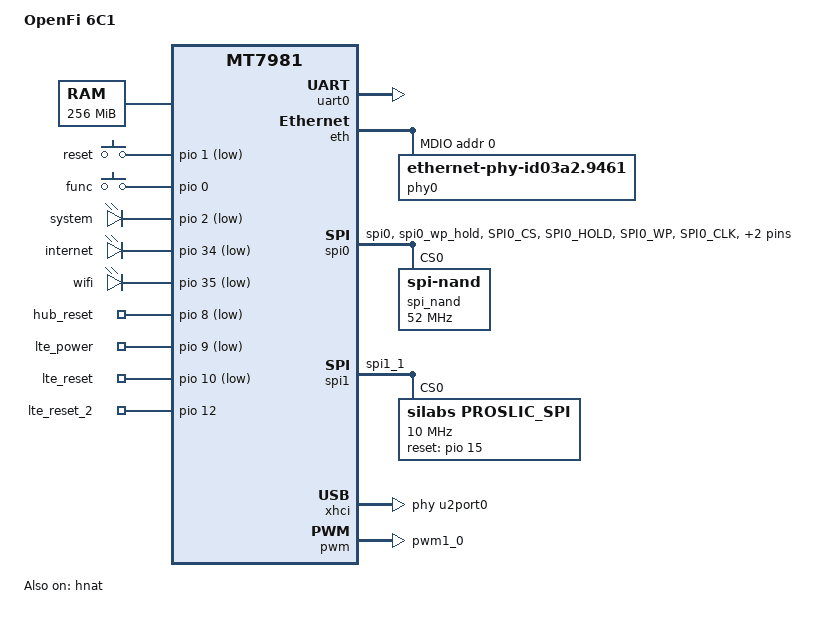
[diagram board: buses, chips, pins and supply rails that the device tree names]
/dts-v1/;
#include "mt7981.dtsi"
/ {
	model = "OpenFi 6C1";
	compatible = "openfi,6c1", "mediatek,mt7981";
	chosen {
		bootargs = "console=ttyS0,115200n1 loglevel=8  \
				earlycon=uart8250,mmio32,0x11002000";
	};

	memory {
		reg = <0 0x40000000 0 0x10000000>;
	};

	gpio-keys {
		compatible = "gpio-keys";

		reset {
			label = "reset";
			linux,code = <KEY_RESTART>;
			gpios = <&pio 1 GPIO_ACTIVE_LOW>;
		};

		func {
			label = "func";
			linux,code = <KEY_CONFIG>;
			gpios = <&pio 0 GPIO_ACTIVE_HIGH>;
		};
	};

	leds {
		compatible = "gpio-leds";

		led_system: led-01 {
			label = "system";
			gpios = <&pio 2 GPIO_ACTIVE_LOW>;
			default-state = "on";
		};

		led_internet: led-02  {
			label = "internet";
			gpios = <&pio 34 GPIO_ACTIVE_LOW>;
			default-state = "on";
		};

		led_wifi: led-03 {
			label = "wifi";
			gpios = <&pio 35 GPIO_ACTIVE_LOW>;
			default-state = "on";
		};
	};

	gpio-export {
		compatible = "gpio-export";

		hub_reset {
			gpio-export,name = "hub_reset";
			gpio-export,output = <0>;
			gpios = <&pio 8 GPIO_ACTIVE_LOW>;
		};

		lte_power {
			gpio-export,name = "lte_power";
			gpio-export,output = <1>;
			gpios = <&pio 9 GPIO_ACTIVE_LOW>;
		};

		lte_reset {
			gpio-export,name = "lte_reset";
			gpio-export,output = <1>;
			gpios = <&pio 10 GPIO_ACTIVE_LOW>;
		};

		lte_reset_2 {
			gpio-export,name = "lte_reset_2";
			gpio-export,output = <0>;
			gpios = <&pio 12 GPIO_ACTIVE_HIGH>;
		};
	};

	nmbm_spim_nand {
		compatible = "generic,nmbm";

		#address-cells = <1>;
		#size-cells = <1>;

		lower-mtd-device = <&spi_nand>;
		forced-create;

		partitions {
			compatible = "fixed-partitions";
			#address-cells = <1>;
			#size-cells = <1>;

			partition@0 {
				label = "BL2";
				reg = <0x00000 0x0100000>;
				read-only;
			};

			partition@100000 {
				label = "u-boot-env";
				reg = <0x0100000 0x0080000>;
			};

			partition@180000 {
				label = "Factory";
				reg = <0x180000 0x0200000>;
			};

			partition@380000 {
				label = "FIP";
				reg = <0x380000 0x0200000>;
			};
			partition@580000 {
				label = "hw";
				reg = <0x580000 0x0080000>;
			};
			partition@600000 {
				label = "cfg";
				reg = <0x600000 0x0080000>;
			};
			partition@680000 {
				label = "ubi";
				reg = <0x680000 0xe980000>;
			};
		};
	};
/*	
	fan: pwm-fan {
		compatible = "pwm-fan";
		cooling-min-state = <0>;
		cooling-max-state = <3>;
		#cooling-cells = <2>;
		pwms = <&pwm 1 50000 1>;
		pinctrl-names = "default";
		cooling-levels = <255 125 80 0>;
	};
*/
};
/*
&cpu_thermal {
	trips {
		cpu_trip_critical: critical {
			temperature = <100000>;
			hysteresis = <2000>;
			type = "critical";
		};

		cpu_trip_hot: hot {
			temperature = <80000>;
			hysteresis = <2000>;
			type = "hot";
		};

		cpu_trip_active: active {
			temperature = <60000>;
			hysteresis = <2000>;
			type = "active";
		};

		cpu_trip_passive: passive {
			temperature = <40000>;
			hysteresis = <2000>;
			type = "passive";
		};
	};

	cooling-maps {
		cpu-active-high {
			cooling-device = <&fan 3 3>;
			trip = <&cpu_trip_critical>;
		};

		cpu-active-low {
			cooling-device = <&fan 2 2>;
			trip = <&cpu_trip_hot>;
		};

		cpu-active {
			cooling-device = <&fan 1 1>;
			trip = <&cpu_trip_active>;
		};

		cpu-passive {
			cooling-device = <&fan 0 0>;
			trip = <&cpu_trip_passive>;
		};
	};
};
*/


&uart0 {
	status = "okay";
};
/*
&watchdog {
	status = "okay";
};
*/

&eth {
	status = "okay";

	gmac0: mac@0 {
		compatible = "mediatek,eth-mac";
		reg = <0>;
		phy-mode = "gmii";
	};

	gmac1: mac@1 {
		compatible = "mediatek,eth-mac";
		reg = <1>;
		phy-mode = "gmii";
		phy-handle = <&phy0>;
	};

	mdio: mdio-bus {
		#address-cells = <1>;
		#size-cells = <0>;

		phy0: phy@0 {
			compatible = "ethernet-phy-id03a2.9461";
			reg = <0>;
			nvmem-cells = <&phy_calibration>;
			nvmem-cell-names = "phy-cal-data";
		};
	};
};

&hnat {
	mtketh-wan = "eth1";
	mtketh-lan = "eth0";
	mtketh-ppd = "eth0";
	mtketh-max-gmac = <2>;
	mtketh-ppe-num = <2>;
	status = "okay";
};


&spi0 {
	pinctrl-names = "default";
	pinctrl-0 = <&spi0_flash_pins>;
	status = "okay";
	spi_nand: spi_nand@0 {
		#address-cells = <1>;
		#size-cells = <1>;
		compatible = "spi-nand";
		reg = <0>;
		spi-max-frequency = <52000000>;
		spi-tx-bus-width = <4>;
		spi-rx-bus-width = <4>;
	};
};

&spi1 {
	pinctrl-names = "default";
	pinctrl-0 = <&spic_pins>;
	status = "okay";

	proslic_spi: proslic_spi@0 {
		compatible = "silabs,proslic_spi";
		reg = <0>;
		spi-max-frequency = <10000000>;
		spi-cpha = <1>;
		spi-cpol = <1>;
		channel_count = <1>;
		debug_level = <4>;       /* 1 = TRC, 2 = DBG, 4 = ERR */
		reset_gpio = <&pio 15 0>;
		ig,enable-spi = <1>;     /* 1: Enable, 0: Disable */
	};
};

&pio {

		pwm0_pin: pwm0-pin-g0 {
				mux {
						function = "pwm";
						groups = "pwm0_0";
				};
		};

		pwm1_pin: pwm1-pin-g0 {
				mux {
						function = "pwm";
						groups = "pwm1_0";
				};
		};

		pwm2_pin: pwm2-pin {
				mux {
						function = "pwm";
						groups = "pwm2";
				};
		};

	spi0_flash_pins: spi0-pins {
		mux {
			function = "spi";
			groups = "spi0", "spi0_wp_hold";
		};

		conf-pu {
			pins = "SPI0_CS", "SPI0_HOLD", "SPI0_WP";
			drive-strength = <MTK_DRIVE_8mA>;
			bias-pull-up = <MTK_PUPD_SET_R1R0_11>;
		};

		conf-pd {
			pins = "SPI0_CLK", "SPI0_MOSI", "SPI0_MISO";
			drive-strength = <MTK_DRIVE_8mA>;
			bias-pull-down = <MTK_PUPD_SET_R1R0_11>;
		};
	};

	spic_pins: spi1-pins {
		mux {
			function = "spi";
			groups = "spi1_1";
		};
	};

	uart1_pins: uart1-pins-g1 {
				mux {
						function = "uart";
						groups = "uart1_1";
				};
		};

	uart2_pins: uart2-pins-g1 {
			mux {
					function = "uart";
					groups = "uart2_1";
				};
		};
};

&xhci {
	mediatek,u3p-dis-msk = <0x0>;
	phys = <&u2port0 PHY_TYPE_USB2>,
	<&u3port0 PHY_TYPE_USB3>;
	status = "okay";
};

&pwm {
	pinctrl-names = "default";
	pinctrl-0 = <&pwm1_pin>;
	status = "okay";
};
